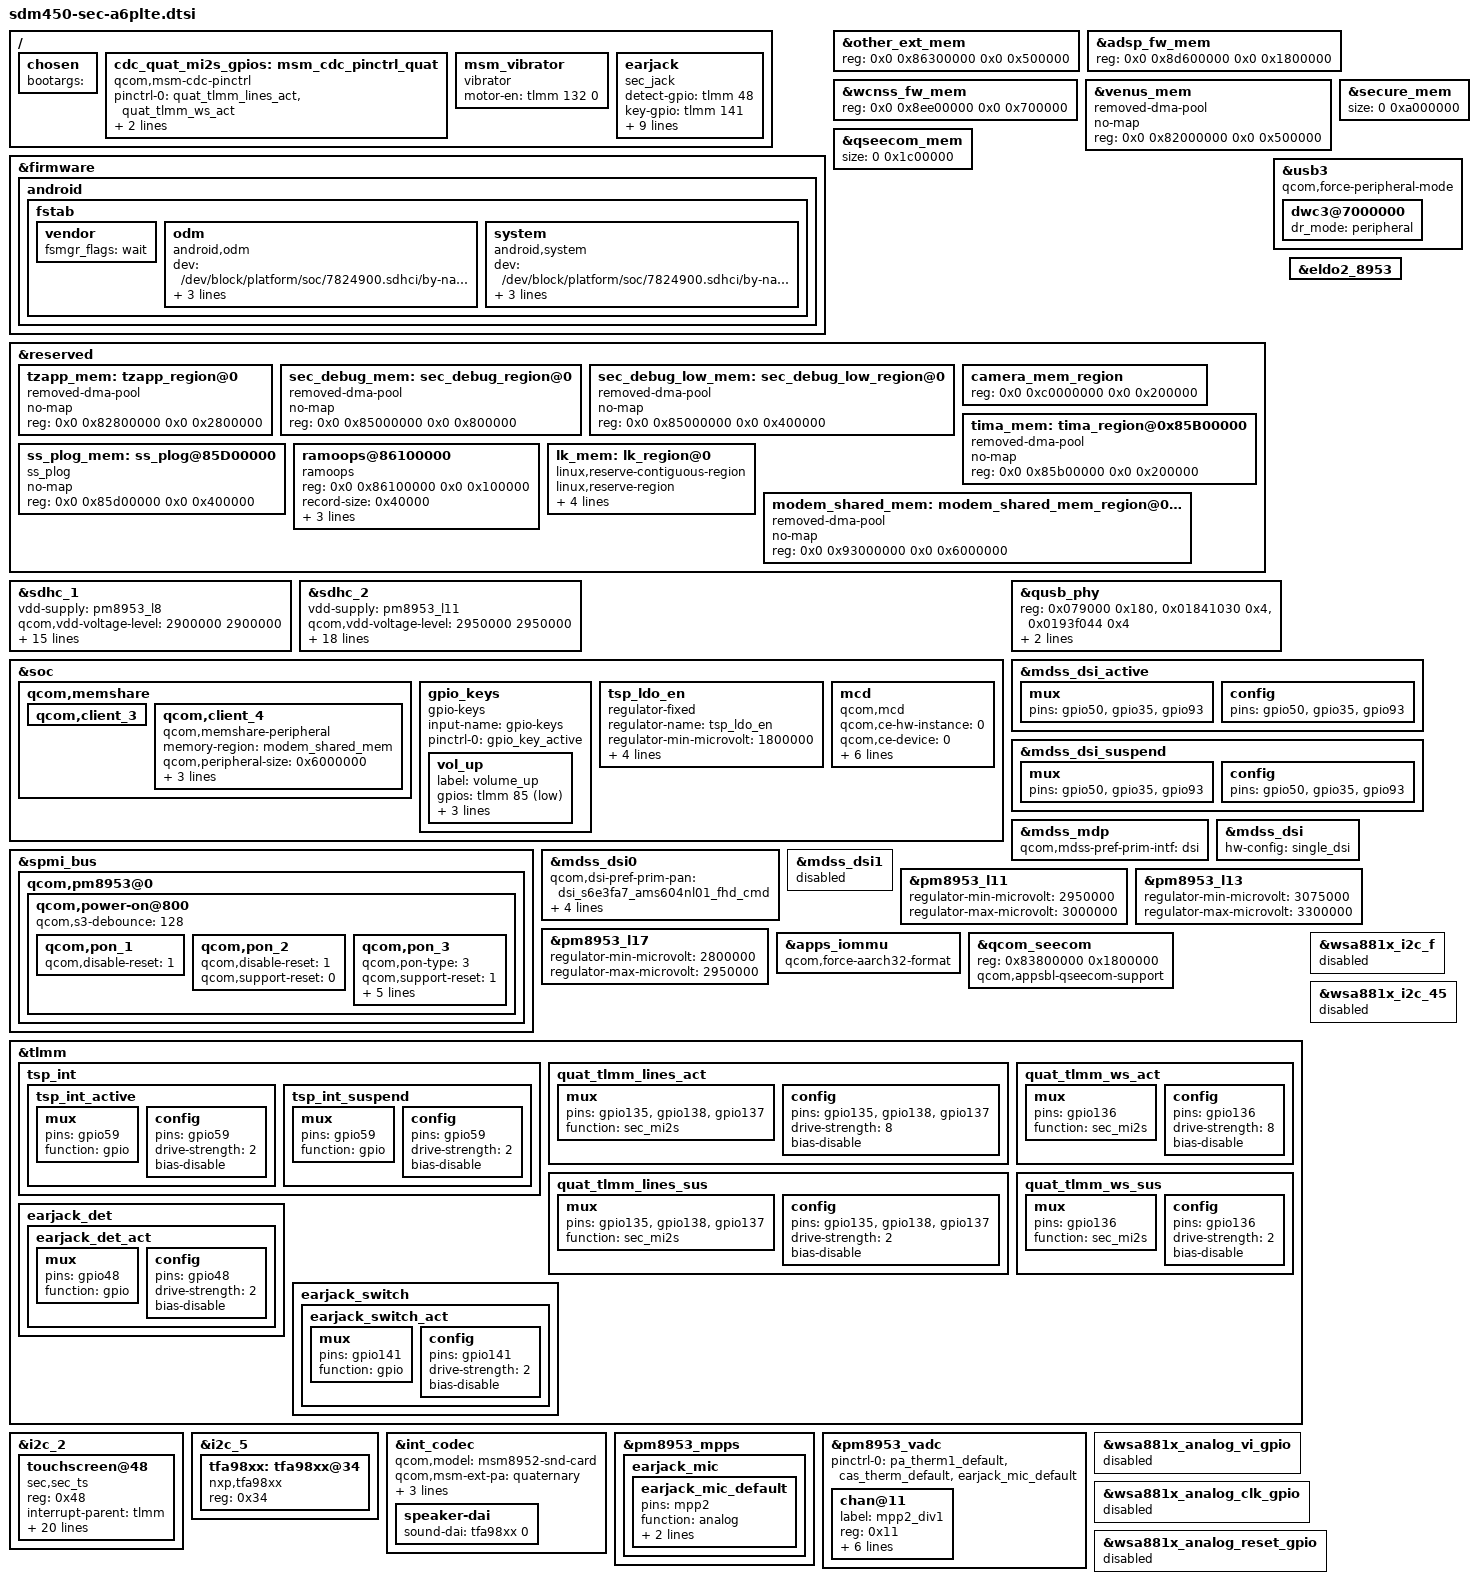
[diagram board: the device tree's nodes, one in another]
/*
 * Samsung Galaxy A6+ (SM-A605FN, a6plte) - SDM450 + PM8953 (no PMI).
 *
 * Board data taken from the stock 3.18 device tree (Rev04) on top of the
 * 4.9 SoC dtsi. The memory map must match the stock one: the modem, ADSP
 * and TrustZone images shipped on the phone are built for it.
 */

#include "sdm450.dtsi"
#include "dsi-panel-s6e3fa7-ams604nl01-fhd-cmd.dtsi"

/ {
	/* Booted by the Samsung bootloader: it patches /memory and the cmdline. */
	chosen {
		bootargs = "";
	};
};

/*
 * Android first-stage init mounts system/vendor/odm from here. The stock
 * flags have "verify" (dm-verity v1); it is dropped on purpose so system
 * can be modified (same change as the 3.18 kernel for this phone).
 */
&firmware {
	android {
		/delete-node/ vbmeta;

		fstab {
			vendor {
				fsmgr_flags = "wait";
			};

			odm {
				compatible = "android,odm";
				dev = "/dev/block/platform/soc/7824900.sdhci/by-name/odm";
				type = "ext4";
				mnt_flags = "ro,barrier=1,discard";
				fsmgr_flags = "wait";
				status = "ok";
			};

			system {
				compatible = "android,system";
				dev = "/dev/block/platform/soc/7824900.sdhci/by-name/system";
				type = "ext4";
				mnt_flags = "ro,barrier=1,discard";
				fsmgr_flags = "wait";
				status = "ok";
			};
		};
	};
};

/* Reserved memory: stock map */
&other_ext_mem {
	reg = <0x0 0x86300000 0x0 0x500000>;
};

&adsp_fw_mem {
	reg = <0x0 0x8d600000 0x0 0x1800000>;
};

&wcnss_fw_mem {
	reg = <0x0 0x8ee00000 0x0 0x700000>;
};

&venus_mem {
	compatible = "removed-dma-pool";
	no-map;
	reg = <0x0 0x82000000 0x0 0x500000>;
	/delete-property/ reusable;
	/delete-property/ alloc-ranges;
	/delete-property/ alignment;
	/delete-property/ size;
};

&secure_mem {
	size = <0 0xa000000>;
};

&qseecom_mem {
	size = <0 0x1c00000>;
};

&reserved {
	tzapp_mem: tzapp_region@0 {
		compatible = "removed-dma-pool";
		no-map;
		reg = <0x0 0x82800000 0x0 0x2800000>;
	};

	sec_debug_mem: sec_debug_region@0 {
		compatible = "removed-dma-pool";
		no-map;
		reg = <0x0 0x85000000 0x0 0x800000>;
	};

	/* The Samsung aboot looks this node up by name and deletes it (as it does with
	 * lk_region@0 and sec_debug_region@0); keep it, as in the stock DT. */
	sec_debug_low_mem: sec_debug_low_region@0 {
		compatible = "removed-dma-pool";
		no-map;
		reg = <0x0 0x85000000 0x0 0x400000>;
	};

	camera_mem_region {
		reg = <0x0 0xc0000000 0x0 0x200000>;
	};

	tima_mem: tima_region@0x85B00000 {
		compatible = "removed-dma-pool";
		no-map;
		reg = <0x0 0x85b00000 0x0 0x200000>;
	};

	ss_plog_mem: ss_plog@85D00000 {
		compatible = "ss_plog";
		no-map;
		reg = <0x0 0x85d00000 0x0 0x400000>;
	};

	/* last kernel messages: /sys/fs/pstore/console-ramoops after a reboot */
	ramoops@86100000 {
		compatible = "ramoops";
		reg = <0x0 0x86100000 0x0 0x100000>;
		record-size = <0x40000>;
		console-size = <0x40000>;
		ftrace-size = <0x40000>;
		pmsg-size = <0x40000>;
	};

	lk_mem: lk_region@0 {
		linux,reserve-contiguous-region;
		linux,reserve-region;
		linux,remove-completely;
		no-map;
		reg = <0x0 0x8f600000 0x0 0x300000>;
		label = "lk_mem";
	};

	modem_shared_mem: modem_shared_mem_region@0x93000000 {
		compatible = "removed-dma-pool";
		no-map;
		reg = <0x0 0x93000000 0x0 0x6000000>;
	};
};

/* eMMC (system, vendor, userdata...): same supplies and speed modes as stock */
&sdhc_1 {
	vdd-supply = <&pm8953_l8>;
	qcom,vdd-voltage-level = <2900000 2900000>;
	qcom,vdd-current-level = <200 570000>;

	vdd-io-supply = <&pm8953_l5>;
	qcom,vdd-io-always-on;
	qcom,vdd-io-lpm-sup;
	qcom,vdd-io-voltage-level = <1800000 1800000>;
	qcom,vdd-io-current-level = <200 325000>;

	pinctrl-names = "active", "sleep";
	pinctrl-0 = <&sdc1_clk_on &sdc1_cmd_on &sdc1_data_on &sdc1_rclk_on>;
	pinctrl-1 = <&sdc1_clk_off &sdc1_cmd_off &sdc1_data_off &sdc1_rclk_off>;

	qcom,clk-rates = <400000 20000000 25000000 50000000 100000000 192000000
								384000000>;
	qcom,nonremovable;
	qcom,bus-speed-mode = "HS400_1p8v", "HS200_1p8v", "DDR_1p8v";

	status = "ok";
};

/* microSD */
&sdhc_2 {
	vdd-supply = <&pm8953_l11>;
	qcom,vdd-voltage-level = <2950000 2950000>;
	qcom,vdd-current-level = <15000 800000>;

	vdd-io-supply = <&pm8953_l12>;
	qcom,vdd-io-voltage-level = <1800000 2950000>;
	qcom,vdd-io-current-level = <200 22000>;

	pinctrl-names = "active", "sleep";
	pinctrl-0 = <&sdc2_clk_on &sdc2_cmd_on &sdc2_data_on &sdc2_cd_on>;
	pinctrl-1 = <&sdc2_clk_off &sdc2_cmd_off &sdc2_data_off>;

	#address-cells = <0>;
	interrupt-parent = <&sdhc_2>;
	interrupts = <0 1 2>;
	#interrupt-cells = <1>;
	interrupt-map-mask = <0xffffffff>;
	interrupt-map = <0 &intc 0 125 0
		1 &intc 0 221 0
		2 &tlmm 133 0>;
	interrupt-names = "hc_irq", "pwr_irq", "status_irq";
	cd-gpios = <&tlmm 133 0x1>;

	qcom,clk-rates = <400000 20000000 25000000 50000000 100000000
								200000000>;
	qcom,bus-speed-mode = "SDR12", "SDR25", "SDR50", "DDR50", "SDR104";

	status = "ok";
};

/* Volume up (volume down / power are on the PMIC PON block) */
&soc {
	/* The Samsung aboot reads qcom,client_4/qcom,peripheral-size (the modem shared
	 * memory) from here and fails hard when the node is missing. Same as stock. */
	qcom,memshare {
		qcom,client_3 {
			/delete-property/ qcom,allocate-boot-time;
		};

		qcom,client_4 {
			compatible = "qcom,memshare-peripheral";
			memory-region = <&modem_shared_mem>;
			qcom,peripheral-size = <0x6000000>;
			qcom,client-id = <3>;
			qcom,allocate-boot-time;
			label = "modem";
		};
	};

	gpio_keys {
		compatible = "gpio-keys";
		input-name = "gpio-keys";
		pinctrl-names = "default";
		pinctrl-0 = <&gpio_key_active>;

		vol_up {
			label = "volume_up";
			gpios = <&tlmm 85 0x1>;
			linux,input-type = <1>;
			linux,code = <115>;
			debounce-interval = <15>;
		};
	};
};

/* Power key (KPDPWR) and volume down (RESIN), reset combo as on stock */
&spmi_bus {
	qcom,pm8953@0 {
		qcom,power-on@800 {
			qcom,s3-debounce = <128>;

			qcom,pon_1 {
				qcom,disable-reset = <1>;
			};

			qcom,pon_2 {
				qcom,disable-reset = <1>;
				qcom,support-reset = <0>;
			};

			qcom,pon_3 {
				qcom,pon-type = <3>;
				qcom,support-reset = <1>;
				qcom,pull-up = <1>;
				qcom,s1-timer = <6720>;
				qcom,s2-timer = <1000>;
				qcom,s2-type = <1>;
				qcom,use-bark;
			};
		};
	};
};

/* USB: peripheral only for now (no extcon / charger driver yet) */
&usb3 {
	qcom,force-peripheral-mode;

	dwc3@7000000 {
		dr_mode = "peripheral";
	};
};

/*
 * QUSB2 PHY as in the stock DT: its own init sequence and no tcsr_clamp_dig_n_1p8
 * (0x193f020 belongs to the A02s TCSR layout; on this board 0x193f044 is the clock
 * scheme select). A wrong PHY setup made the host fail with "device descriptor read/64,
 * error -71".
 */
&qusb_phy {
	reg = <0x079000 0x180>,
		<0x01841030 0x4>,
		<0x0193f044 0x4>;
	reg-names = "qusb_phy_base", "ref_clk_addr",
		"tcsr_phy_clk_scheme_sel";
	qcom,qusb-phy-init-seq = <0xc0 0x80
				0x43 0x84
				0x81 0x88
				0xc0 0x8c
				0x30 0x08
				0x79 0x0c
				0x21 0x10
				0x14 0x9c
				0x9f 0x1c
				0x00 0x18>;
};

/* On the Qualcomm MTP this always-on rail is enabled by GPIO 50; on the A6+ GPIO 50 is
 * the panel reset line (mdss_dsi0), so it must not be claimed here (gpio_request -EBUSY
 * made the DSI controller probe fail and left the display black). */
&eldo2_8953 {
	/delete-property/ gpio;
	/delete-property/ enable-active-high;
};

/*
 * Display: S6E3FA7 on DSI0. GPIO 50 is the panel reset, 35 and 93 the panel
 * power enables (driven by the "active" pin state, as on stock).
 */
&mdss_dsi_active {
	mux {
		pins = "gpio50", "gpio35", "gpio93";
	};

	config {
		pins = "gpio50", "gpio35", "gpio93";
	};
};

&mdss_dsi_suspend {
	mux {
		pins = "gpio50", "gpio35", "gpio93";
	};

	config {
		pins = "gpio50", "gpio35", "gpio93";
	};
};

&mdss_mdp {
	qcom,mdss-pref-prim-intf = "dsi";
};

&mdss_dsi {
	hw-config = "single_dsi";
};

&mdss_dsi0 {
	qcom,dsi-pref-prim-pan = <&dsi_s6e3fa7_ams604nl01_fhd_cmd>;
	pinctrl-names = "mdss_default", "mdss_sleep";
	pinctrl-0 = <&mdss_dsi_active &mdss_te_active>;
	pinctrl-1 = <&mdss_dsi_suspend &mdss_te_suspend>;

	qcom,platform-te-gpio = <&tlmm 24 0>;
	qcom,platform-reset-gpio = <&tlmm 50 0>;
	/delete-property/ qcom,platform-bklight-en-gpio;
};

&mdss_dsi1 {
	status = "disabled";
};

/* Voltage ranges as on stock (SD card core, panel/vdd rails) */
&pm8953_l11 {
	regulator-min-microvolt = <2950000>;
	regulator-max-microvolt = <3000000>;
};

&pm8953_l13 {
	regulator-min-microvolt = <3075000>;
	regulator-max-microvolt = <3300000>;
};

&pm8953_l17 {
	regulator-min-microvolt = <2800000>;
	regulator-max-microvolt = <2950000>;
};

/* The stock TZ keeps the APPS context banks in AArch32 format */
&apps_iommu {
	qcom,force-aarch32-format;
};

/* Same secure-app region as the stock DT (inside tzapp_region): the Samsung TZ
 * rejects the registration of any other address (scm 0x72000105 -> -2). */
&qcom_seecom {
	reg = <0x83800000 0x1800000>;
	/delete-property/ qcom,commonlib64-loaded-by-uefi;
	qcom,appsbl-qseecom-support;
};

/* Touchscreen: Samsung sec_ts on BLSP1 QUP2 (i2c_2), supplied by a GPIO-controlled 1.8 V LDO. */
&tlmm {
	tsp_int {
		tsp_int_active: tsp_int_active {
			mux {
				pins = "gpio59";
				function = "gpio";
			};
			config {
				pins = "gpio59";
				drive-strength = <2>;
				bias-disable;
			};
		};
		tsp_int_suspend: tsp_int_suspend {
			mux {
				pins = "gpio59";
				function = "gpio";
			};
			config {
				pins = "gpio59";
				drive-strength = <2>;
				bias-disable;
			};
		};
	};
};

&soc {
	tsp_ldo_en: tsp_ldo_en {
		compatible = "regulator-fixed";
		regulator-name = "tsp_ldo_en";
		regulator-min-microvolt = <1800000>;
		regulator-max-microvolt = <1800000>;
		gpio = <&tlmm 139 0>;
		enable-active-high;
		regulator-boot-on;
	};
};

&i2c_2 {
	status = "okay";

	touchscreen@48 {
		compatible = "sec,sec_ts";
		reg = <0x48>;
		interrupt-parent = <&tlmm>;
		interrupts = <59 0>;
		pinctrl-names = "on_state", "off_state";
		pinctrl-0 = <&tsp_int_active>;
		pinctrl-1 = <&tsp_int_suspend>;
		sec,irq_gpio = <&tlmm 59 0>;
		sec,irq_type = <0x2008>;
		sec,max_coords = <4096 4096>;
		sec,num_lines = <30 15>;
		sec,use_ic_resolution;
		sec,mis_cal_check = <1>;
		sec,use_gpio_ldo;
		sec,regulator_avdd = "tsp_ldo_en";
		sec,regulator_boot_on;
		sec,grip_area = <512>;
		sec,bringup = <3>;
		sec,tclm_level = <2>;
		sec,afe_base = <0x104>;
		sec,project_name = "A6plus", "A605F";
		sec,firmware_name = "tsp_sec/y661_a6plus.fw", "tsp_sec/y661_a6plus.fw";
		sec,factory_item_version = <1>;
		status = "okay";
	};
};

#include "sdm450-sec-a6plte-battery.dtsi"

/* Audio: NXP TFA9872 speaker amplifier on the quaternary MI2S (as on the stock DT) */
&tlmm {
	quat_tlmm_lines_act: quat_tlmm_lines_act {
		mux {
			pins = "gpio135", "gpio138", "gpio137";
			function = "sec_mi2s";
		};
		config {
			pins = "gpio135", "gpio138", "gpio137";
			drive-strength = <8>;
			bias-disable;
		};
	};

	quat_tlmm_lines_sus: quat_tlmm_lines_sus {
		mux {
			pins = "gpio135", "gpio138", "gpio137";
			function = "sec_mi2s";
		};
		config {
			pins = "gpio135", "gpio138", "gpio137";
			drive-strength = <2>;
			bias-disable;
		};
	};

	quat_tlmm_ws_act: quat_tlmm_ws_act {
		mux {
			pins = "gpio136";
			function = "sec_mi2s";
		};
		config {
			pins = "gpio136";
			drive-strength = <8>;
			bias-disable;
		};
	};

	quat_tlmm_ws_sus: quat_tlmm_ws_sus {
		mux {
			pins = "gpio136";
			function = "sec_mi2s";
		};
		config {
			pins = "gpio136";
			drive-strength = <2>;
			bias-disable;
		};
	};
};

/ {
	cdc_quat_mi2s_gpios: msm_cdc_pinctrl_quat {
		compatible = "qcom,msm-cdc-pinctrl";
		pinctrl-names = "aud_active", "aud_sleep";
		pinctrl-0 = <&quat_tlmm_lines_act &quat_tlmm_ws_act>;
		pinctrl-1 = <&quat_tlmm_lines_sus &quat_tlmm_ws_sus>;
	};
};

&i2c_5 {
	status = "okay";

	tfa98xx: tfa98xx@34 {
		#sound-dai-cells = <1>;
		compatible = "nxp,tfa98xx";
		reg = <0x34>;
	};
};

&int_codec {
	qcom,model = "msm8952-snd-card";
	qcom,msm-ext-pa = "quaternary";
	/* gpio93 (pri/quin lines) is the panel supply on this board: do not touch it */
	/delete-property/ qcom,pri-mi2s-gpios;
	/delete-property/ qcom,quin-mi2s-gpios;
	/* No WSA881x amplifiers on the A6+ (disabled below): without this the machine driver defers forever */
	/delete-property/ asoc-wsa-codec-names;
	/delete-property/ asoc-wsa-codec-prefixes;
	/delete-property/ qcom,wsa-max-devs;
	/delete-property/ qcom,wsa-devs;
	/delete-property/ qcom,wsa-aux-dev-prefix;
	qcom,quat-mi2s-gpios = <&cdc_quat_mi2s_gpios>;
	qcom,nxp-amp-conf = <0x1006>;
	speaker-amps = <&tfa98xx>;

	speaker-dai {
		sound-dai = <&tfa98xx 0>;
	};
};
/ {
	/* vibration motor, switched by TLMM gpio 132 (stock "msm_vibrator") */
	msm_vibrator {
		compatible = "vibrator";
		motor-en = <&tlmm 132 0>;
	};
};

/* 3.5mm jack: plug on gpio 48, headset button on gpio 141, microphone line read on MPP2 (VADC channel 0x11) */
&tlmm {
	earjack_det {
		earjack_det_act: earjack_det_act {
			mux {
				pins = "gpio48";
				function = "gpio";
			};
			config {
				pins = "gpio48";
				drive-strength = <2>;
				bias-disable;
			};
		};
	};
	earjack_switch {
		earjack_switch_act: earjack_switch_act {
			mux {
				pins = "gpio141";
				function = "gpio";
			};
			config {
				pins = "gpio141";
				drive-strength = <2>;
				bias-disable;
			};
		};
	};
};

&pm8953_mpps {
	earjack_mic {
		earjack_mic_default: earjack_mic_default {
			pins = "mpp2";
			function = "analog";
			input-enable;
			qcom,amux-route = <1>;
		};
	};
};

&pm8953_vadc {
	pinctrl-0 = <&pa_therm1_default &cas_therm_default &earjack_mic_default>;

	chan@11 {
		label = "mpp2_div1";
		reg = <0x11>;
		qcom,decimation = <0>;
		qcom,pre-div-channel-scaling = <0>;
		qcom,calibration-type = "absolute";
		qcom,scale-function = <0>;
		qcom,hw-settle-time = <5>;
		qcom,fast-avg-setup = <0>;
	};
};

/ {
	earjack {
		compatible = "sec_jack";
		detect-gpio = <&tlmm 48 0>;
		key-gpio = <&tlmm 141 0>;
		det-dbtime = <100>;
		key-dbtime = <28>;
		earjack-adc-channel = <0x11>;
		qcom,earjack-read-vadc = <&pm8953_vadc>;
		/* adc_high(mV) delay(us) check_count jack_type (2 = 3 pole, 1 = 4 pole) */
		det-zones = <0 10000 10 2>,
			    <970 10000 10 2>,
			    <971 10000 10 1>,
			    <9999 10000 10 1>;
		/* key code, adc_low(mV), adc_high(mV): MEDIA, VOICECOMMAND, VOLUMEUP, VOLUMEDOWN */
		but-zones = <226 0 308>,
			    <582 309 352>,
			    <115 353 470>,
			    <114 471 810>;
		pinctrl-names = "earjack_gpio_active";
		pinctrl-0 = <&earjack_det_act &earjack_switch_act>;
	};
};

#include "sdm450-sec-a6plte-sensors.dtsi"
#include "sdm450-sec-a6plte-camera.dtsi"

/* The A6+ has no WSA881x speaker amplifiers: free GPIO 94 for the camera */
&wsa881x_i2c_f { status = "disabled"; };
&wsa881x_i2c_45 { status = "disabled"; };
&wsa881x_analog_vi_gpio { status = "disabled"; };
&wsa881x_analog_clk_gpio { status = "disabled"; };
&wsa881x_analog_reset_gpio { status = "disabled"; };

/* Trustonic Kinibi TEE (as in the stock device tree) */
&soc {
	mcd {
		compatible = "qcom,mcd";
		qcom,ce-hw-instance = <0>;
		qcom,ce-device = <0>;
		interrupts = <0 319 0>;
		interrupt-names = "mcd_irq";
		clocks = <&clock_gcc clk_crypto_clk_src>,
			 <&clock_gcc clk_gcc_crypto_clk>,
			 <&clock_gcc clk_gcc_crypto_ahb_clk>,
			 <&clock_gcc clk_gcc_crypto_axi_clk>;
		clock-names = "core_clk_src", "core_clk", "iface_clk", "bus_clk";
		qcom,ce-opp-freq = <100000000>;
	};
};
